# STM32MP157 register map
File version: 1.7
CPU: CM4 r0p1, little endian, no MPU, FPU, 4 interrupt priority bits
Registers are 32-bit, read-write, reset 0x0 unless marked. A register's access mark holds for its fields unless they carry their own. Offsets are from the block's base; [hi:lo] are bit positions; {n}, {i} and the like mark numbered series.

## IWDG1
Base 0x5C003000
Same registers: IWDG2 0x5A002000
0x00 KR 16-bit wo — Key register
  [15:0] KEY
0x04 PR 16-bit reset 0x7 — Prescaler register
  [2:0] PR
0x08 RLR 16-bit reset 0xFFF — Reload register
  [11:0] RL
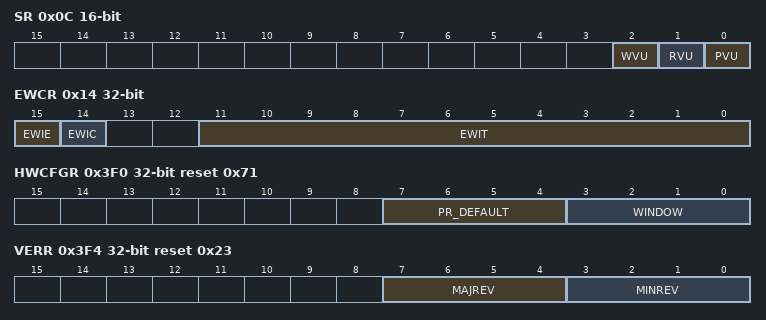
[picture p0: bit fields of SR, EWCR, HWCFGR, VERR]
0x0C SR 16-bit ro — Status register
  [2] WVU, [1] RVU, [0] PVU
0x10 WINR 16-bit reset 0xFFF — Window register
  [11:0] WIN
0x14 EWCR — IWDG early wake-up interrupt register
  [15] EWIE, [14] EWIC, [11:0] EWIT
0x3F0 HWCFGR ro reset 0x71 — IWDG hardware configuration register
  [7:4] PR_DEFAULT, [3:0] WINDOW
0x3F4 VERR ro reset 0x23 — IWDG version register
  [7:4] MAJREV, [3:0] MINREV
0x3F8 IDR ro reset 0x120041 — IWDG identification register
  [31:0] ID
0x3FC SIDR ro reset 0xA3C5DD01 — IWDG size identification register
  [31:0] SID

## LPTIM1
Base 0x40009000
Same registers: LPTIM2 0x50021000, LPTIM3 0x50022000, LPTIM4 0x50023000, LPTIM5 0x50024000
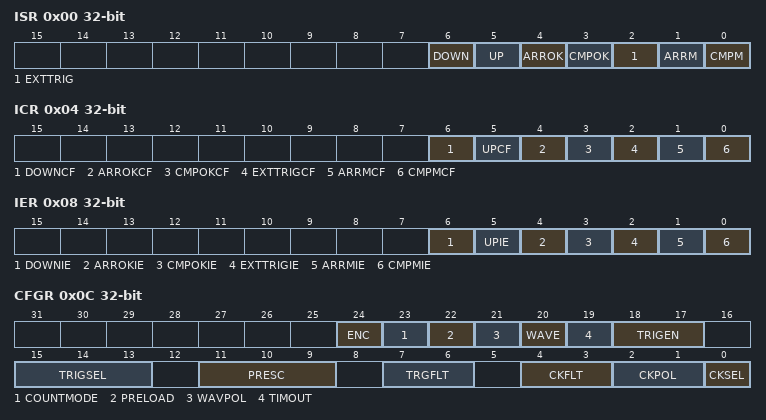
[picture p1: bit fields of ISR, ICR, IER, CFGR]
0x00 ISR ro — LPTIM interrupt and status register
  [6] DOWN, [5] UP, [4] ARROK, [3] CMPOK, [2] EXTTRIG, [1] ARRM, [0] CMPM
0x04 ICR wo — LPTIM interrupt clear register
  [6] DOWNCF, [5] UPCF, [4] ARROKCF, [3] CMPOKCF, [2] EXTTRIGCF, [1] ARRMCF, [0] CMPMCF
0x08 IER — LPTIM interrupt enable register
  [6] DOWNIE, [5] UPIE, [4] ARROKIE, [3] CMPOKIE, [2] EXTTRIGIE, [1] ARRMIE, [0] CMPMIE
0x0C CFGR — LPTIM configuration register
  [24] ENC, [23] COUNTMODE, [22] PRELOAD, [21] WAVPOL, [20] WAVE, [19] TIMOUT, [18:17] TRIGEN, [15:13] TRIGSEL, [11:9] PRESC, [7:6] TRGFLT, [4:3] CKFLT, [2:1] CKPOL, [0] CKSEL
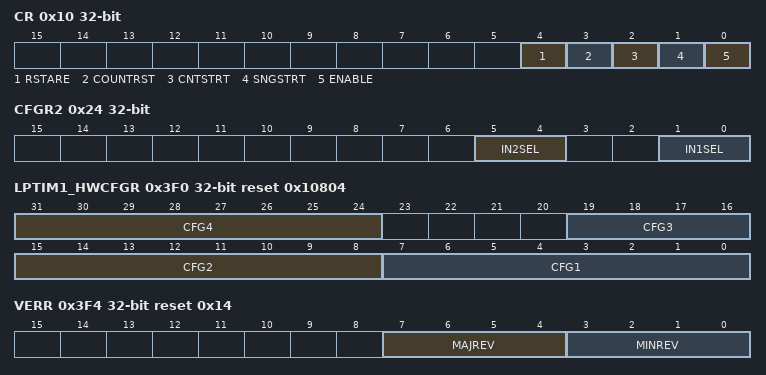
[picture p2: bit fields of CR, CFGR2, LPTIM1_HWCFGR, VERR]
0x10 CR — LPTIM control register
  [4] RSTARE, [3] COUNTRST, [2] CNTSTRT, [1] SNGSTRT, [0] ENABLE
0x14 CMP — LPTIM compare register
  [15:0] CMP
0x18 ARR reset 0x1 — LPTIM autoreload register
  [15:0] ARR
0x1C CNT ro — LPTIM counter register
  [15:0] CNT
0x24 CFGR2 — LPTIM configuration register 2
  [5:4] IN2SEL, [1:0] IN1SEL
0x3F0 LPTIM1_HWCFGR ro reset 0x10804 — LPTIM 1 peripheral hardware configuration register
  [31:24] CFG4, [19:16] CFG3, [15:8] CFG2, [7:0] CFG1
0x3F4 VERR ro reset 0x14 — LPTIM peripheral version identification register
  [7:4] MAJREV, [3:0] MINREV
0x3F8 PIDR ro reset 0x120011 — LPTIM peripheral type identification register
  [31:0] P_ID
0x3FC SIDR ro reset 0xA3C5DD01 — LPTIM registers map size identification register
  [31:0] S_ID

## MDIOS
Base 0x4001C000
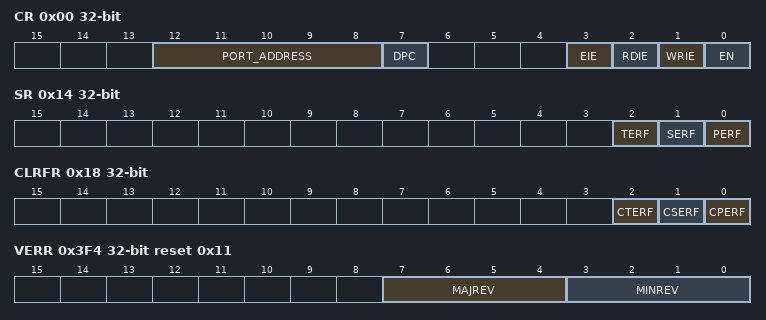
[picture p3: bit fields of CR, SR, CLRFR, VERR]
0x00 CR — MDIOS configuration register
  [12:8] PORT_ADDRESS, [7] DPC, [3] EIE, [2] RDIE, [1] WRIE, [0] EN
0x04 WRFR ro — MDIOS write flag register
  [31:0] WRF
0x08 CWRFR — MDIOS clear write flag register
  [31:0] CWRF
0x0C RDFR ro — MDIOS read flag register
  [31:0] RDF
0x10 CRDFR — MDIOS clear read flag register
  [31:0] CRDF
0x14 SR ro — MDIOS status register
  [2] TERF, [1] SERF, [0] PERF
0x18 CLRFR — MDIOS clear flag register
  [2] CTERF, [1] CSERF, [0] CPERF
{0x100+4i} DINR{i} ro (i=0..31) — MDIOS input data register
  [15:0] DIN
0x180 DOUTR0 ro — MDIOS input data register
  [15:0] DOUT
0x184 DOUTR1 ro — MDIOS input data register
  [15:0] DOUT
{0x180+4i} DOUTR{i} ro (i=2..31) — MDIOS output data register
  [15:0] DOUT
0x3F0 HWCFGR ro reset 0x20 — MDIOS HW configuration register
  [7:0] NBREG
0x3F4 VERR ro reset 0x11 — MDIOS version register
  [7:4] MAJREV, [3:0] MINREV
0x3F8 IPIDR ro reset 0x180001 — MDIOS identification register
  [31:0] ID
0x3FC SIDR ro reset 0xA3C5DD01 — MDIOS size identification register
  [31:0] SID

## MDMA — MDMA1
Base 0x58000000
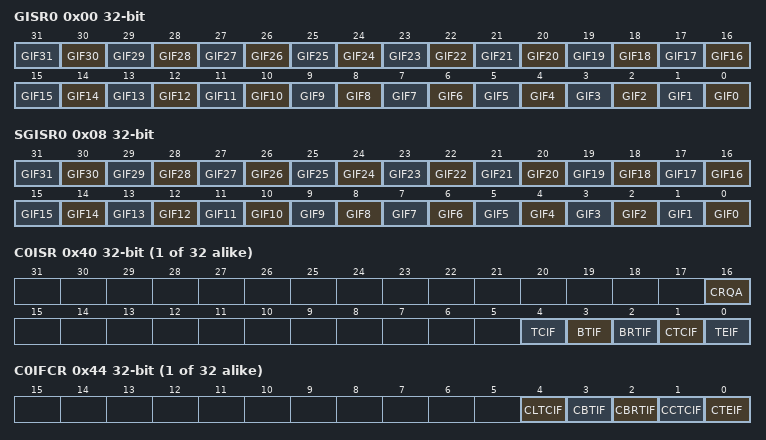
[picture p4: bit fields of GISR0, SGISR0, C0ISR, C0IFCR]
0x00 GISR0 ro — MDMA global interrupt/status register
  [n] GIF{n} (n=0..31)
0x08 SGISR0 ro — MDMA secure global interrupt/status register
  [n] GIF{n} (n=0..31)
{0x40+0x40*i} C{i}ISR ro (i=0..31) — MDMA channel {i} interrupt/status register
  [16] CRQA, [4] TCIF, [3] BTIF, [2] BRTIF, [1] CTCIF, [0] TEIF
{0x44+0x40*i} C{i}IFCR wo (i=0..31) — MDMA channel {i} interrupt flag clear register
  [4] CLTCIF, [3] CBTIF, [2] CBRTIF, [1] CCTCIF, [0] CTEIF
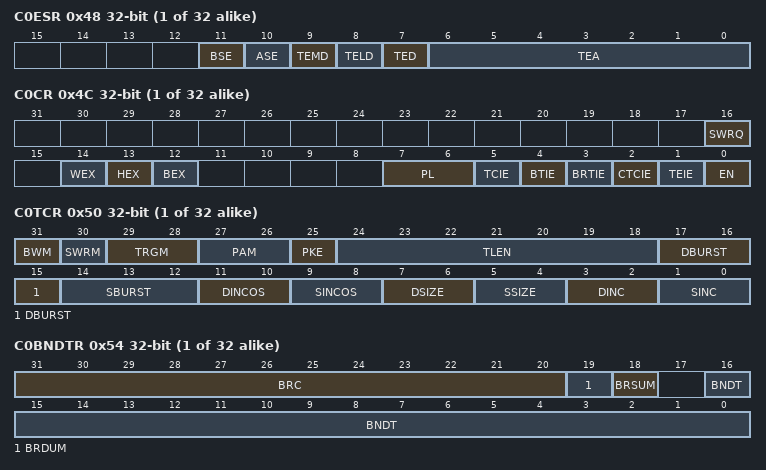
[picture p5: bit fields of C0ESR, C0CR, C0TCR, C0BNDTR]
{0x48+0x40*i} C{i}ESR ro (i=0..31) — MDMA channel {i} error status register
  [11] BSE, [10] ASE, [9] TEMD, [8] TELD, [7] TED, [6:0] TEA
{0x4C+0x40*i} C{i}CR access per field (i=0..31) — This register is used to control the concerned channel.
  [16] SWRQ wo, [14] WEX rw, [13] HEX rw, [12] BEX rw, [7:6] PL rw, [5] TCIE rw, [4] BTIE rw, [3] BRTIE rw, [2] CTCIE rw, [1] TEIE rw, [0] EN rw
{0x50+0x40*i} C{i}TCR (i=0..31) — This register is used to configure the concerned channel. In Linked List mode, at the end of a block (single or last block in repeated block transfer mode), this register will be loaded from memory (from address given by current LAR[31:0] + 0x00).
  [31] BWM, [30] SWRM, [29:28] TRGM, [27:26] PAM, [25] PKE, [24:18] TLEN, [17:15] DBURST, [14:12] SBURST, [11:10] DINCOS, [9:8] SINCOS, [7:6] DSIZE, [5:4] SSIZE, [3:2] DINC, [1:0] SINC
{0x54+0x40*i} C{i}BNDTR (i=0..31) — In Linked List mode, at the end of a block (single or last block in repeated block transfer mode), this register will be loaded from memory (from address given by current LAR[31:0] + 0x04).
  [31:20] BRC, [19] BRDUM, [18] BRSUM, [16:0] BNDT
{0x58+0x40*i} C{i}SAR (i=0..31) — In Linked List mode, at the end of a Block (single or last Block in repeated Block transfer mode), this register will be loaded from memory (from address given by current LAR[31:0] + 0x08).
  [31:0] SAR
{0x5C+0x40*i} C{i}DAR (i=0..31) — In Linked List mode, at the end of a block (single or last block in repeated block transfer mode), this register will be loaded from memory (from address given by current LAR[31:0] + 0x0C). M
  [31:0] DAR
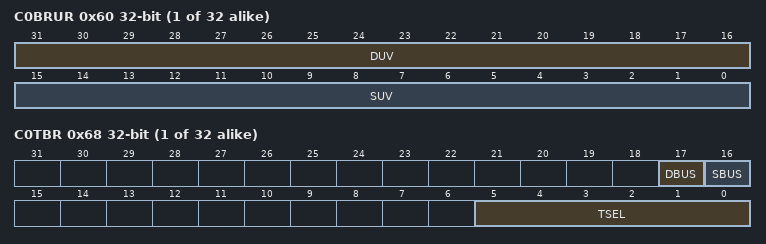
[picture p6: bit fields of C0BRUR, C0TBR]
{0x60+0x40*i} C{i}BRUR (i=0..31) — In Linked List mode, at the end of a block (single or last block in repeated block transfer mode), this register will be loaded from memory (from address given by current LAR[31:0] + 0x10).
  [31:16] DUV, [15:0] SUV
{0x64+0x40*i} C{i}LAR (i=0..31) — In Linked List mode, at the end of a block (single or last block in repeated block transfer mode), this register will be loaded from memory (from address given by current LAR[31:0] + 0x14). The new value is only taken into account after all registers are updated, for the next end of block.
  [31:0] LAR
{0x68+0x40*i} C{i}TBR (i=0..31) — In Linked List mode, at the end of a block (single or last block in repeated block transfer mode), this register will be loaded from memory (from address given by current LAR[31:0] + 0x18).
  [17] DBUS, [16] SBUS, [5:0] TSEL
{0x70+0x40*i} C{i}MAR (i=0..31) — In Linked List mode, at the end of a block (single or last block in repeated block transfer mode), this register will be loaded from memory (from address given by current LAR[31:0] + 0x20).
  [31:0] MAR
{0x74+0x40*i} C{i}MDR (i=0..31) — In Linked List mode, at the end of a block (single or last block in repeated block transfer mode), this register will be loaded from memory (from address given by current LAR[31:0] + 0x24).
  [31:0] MDR
